AUTOSAR XML (schema 4-3-0)
package /PCM_Package
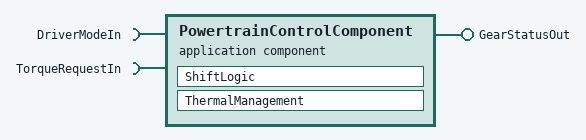
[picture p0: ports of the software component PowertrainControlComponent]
  application sw component type PowertrainControlComponent: category=ECU
    provide port GearStatusOut
    require port DriverModeIn
    require port TorqueRequestIn
    internal behavior PowertrainBehavior
      timing event Periodic10ms: period=0.01
      runnable ShiftLogic: can-be-invited-concurrently=false, minimum-start-interval=0.008
      runnable ThermalManagement: can-be-invited-concurrently=false, minimum-start-interval=0.02
      data VehicleSpeed: type=uint16
      data RequestedTorque: type=int16
    parameter data prototype MaxGear: type=uint8, sw-valuation=numerical-value=8
